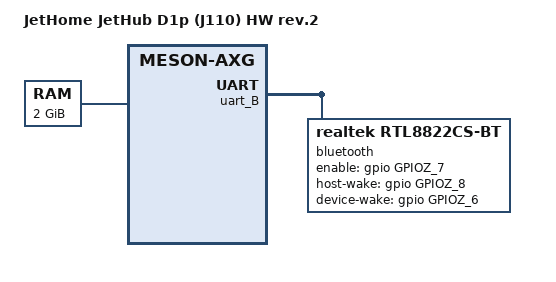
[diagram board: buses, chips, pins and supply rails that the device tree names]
/dts-v1/;
#include "meson-axg-jethome-jethub-j1xx.dtsi"
/ {
	compatible = "jethome,jethub-j110", "amlogic,a113d", "amlogic,meson-axg";
	model = "JetHome JetHub D1p (J110) HW rev.2";
	memory@0 {
		device_type = "memory";
		reg = <0x0 0x0 0x0 0x80000000>;
	};
};
&sd_emmc_b {
	broken-cd; 
};
&uart_B {
	bluetooth {
		compatible = "realtek,rtl8822cs-bt";
		enable-gpios  = <&gpio GPIOZ_7 GPIO_ACTIVE_HIGH>;
		host-wake-gpios = <&gpio GPIOZ_8 GPIO_ACTIVE_HIGH>;
		device-wake-gpios = <&gpio GPIOZ_6 GPIO_ACTIVE_HIGH>;
	};
};
